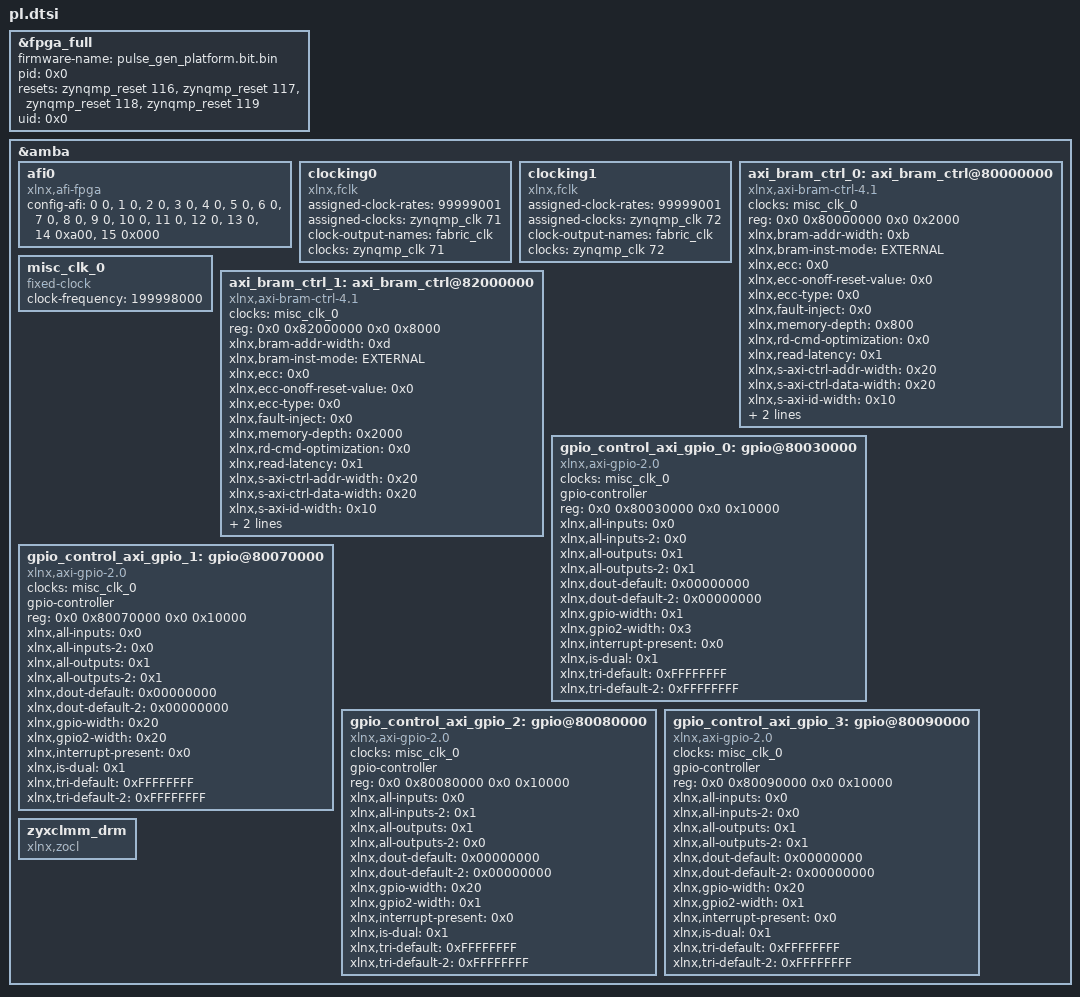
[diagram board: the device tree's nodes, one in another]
/*
 * CAUTION: This file is automatically generated by Xilinx.
 * Version: XSCT 2022.2
 * Today is: Fri Jul 31 22:00:29 2026
 */


/dts-v1/;
/plugin/;
/ {
	fragment@0 {
		target = <&fpga_full>;
		overlay0: __overlay__ {
			#address-cells = <2>;
			#size-cells = <2>;
			firmware-name = "pulse_gen_platform.bit.bin";
			pid = <0x0>;
			resets = <&zynqmp_reset 116>, <&zynqmp_reset 117>, <&zynqmp_reset 118>, <&zynqmp_reset 119>;
			uid = <0x0>;
		};
	};
	fragment@1 {
		target = <&amba>;
		overlay1: __overlay__ {
			afi0: afi0 {
				compatible = "xlnx,afi-fpga";
				config-afi = < 0 0>, <1 0>, <2 0>, <3 0>, <4 0>, <5 0>, <6 0>, <7 0>, <8 0>, <9 0>, <10 0>, <11 0>, <12 0>, <13 0>, <14 0xa00>, <15 0x000>;
			};
			clocking0: clocking0 {
				#clock-cells = <0>;
				assigned-clock-rates = <99999001>;
				assigned-clocks = <&zynqmp_clk 71>;
				clock-output-names = "fabric_clk";
				clocks = <&zynqmp_clk 71>;
				compatible = "xlnx,fclk";
			};
			clocking1: clocking1 {
				#clock-cells = <0>;
				assigned-clock-rates = <99999001>;
				assigned-clocks = <&zynqmp_clk 72>;
				clock-output-names = "fabric_clk";
				clocks = <&zynqmp_clk 72>;
				compatible = "xlnx,fclk";
			};
		};
	};
	fragment@2 {
		target = <&amba>;
		overlay2: __overlay__ {
			#address-cells = <2>;
			#size-cells = <2>;
			axi_bram_ctrl_0: axi_bram_ctrl@80000000 {
				/* This is a place holder node for a custom IP, user may need to update the entries */
				clock-names = "s_axi_aclk";
				clocks = <&misc_clk_0>;
				compatible = "xlnx,axi-bram-ctrl-4.1";
				reg = <0x0 0x80000000 0x0 0x2000>;
				xlnx,bram-addr-width = <0xb>;
				xlnx,bram-inst-mode = "EXTERNAL";
				xlnx,ecc = <0x0>;
				xlnx,ecc-onoff-reset-value = <0x0>;
				xlnx,ecc-type = <0x0>;
				xlnx,fault-inject = <0x0>;
				xlnx,memory-depth = <0x800>;
				xlnx,rd-cmd-optimization = <0x0>;
				xlnx,read-latency = <0x1>;
				xlnx,s-axi-ctrl-addr-width = <0x20>;
				xlnx,s-axi-ctrl-data-width = <0x20>;
				xlnx,s-axi-id-width = <0x10>;
				xlnx,s-axi-supports-narrow-burst = <0x1>;
				xlnx,single-port-bram = <0x1>;
			};
			misc_clk_0: misc_clk_0 {
				#clock-cells = <0>;
				clock-frequency = <199998000>;
				compatible = "fixed-clock";
			};
			axi_bram_ctrl_1: axi_bram_ctrl@82000000 {
				/* This is a place holder node for a custom IP, user may need to update the entries */
				clock-names = "s_axi_aclk";
				clocks = <&misc_clk_0>;
				compatible = "xlnx,axi-bram-ctrl-4.1";
				reg = <0x0 0x82000000 0x0 0x8000>;
				xlnx,bram-addr-width = <0xd>;
				xlnx,bram-inst-mode = "EXTERNAL";
				xlnx,ecc = <0x0>;
				xlnx,ecc-onoff-reset-value = <0x0>;
				xlnx,ecc-type = <0x0>;
				xlnx,fault-inject = <0x0>;
				xlnx,memory-depth = <0x2000>;
				xlnx,rd-cmd-optimization = <0x0>;
				xlnx,read-latency = <0x1>;
				xlnx,s-axi-ctrl-addr-width = <0x20>;
				xlnx,s-axi-ctrl-data-width = <0x20>;
				xlnx,s-axi-id-width = <0x10>;
				xlnx,s-axi-supports-narrow-burst = <0x1>;
				xlnx,single-port-bram = <0x1>;
			};
			gpio_control_axi_gpio_0: gpio@80030000 {
				#gpio-cells = <2>;
				clock-names = "s_axi_aclk";
				clocks = <&misc_clk_0>;
				compatible = "xlnx,axi-gpio-2.0", "xlnx,xps-gpio-1.00.a";
				gpio-controller ;
				reg = <0x0 0x80030000 0x0 0x10000>;
				xlnx,all-inputs = <0x0>;
				xlnx,all-inputs-2 = <0x0>;
				xlnx,all-outputs = <0x1>;
				xlnx,all-outputs-2 = <0x1>;
				xlnx,dout-default = <0x00000000>;
				xlnx,dout-default-2 = <0x00000000>;
				xlnx,gpio-width = <0x1>;
				xlnx,gpio2-width = <0x3>;
				xlnx,interrupt-present = <0x0>;
				xlnx,is-dual = <0x1>;
				xlnx,tri-default = <0xFFFFFFFF>;
				xlnx,tri-default-2 = <0xFFFFFFFF>;
			};
			gpio_control_axi_gpio_1: gpio@80070000 {
				#gpio-cells = <2>;
				clock-names = "s_axi_aclk";
				clocks = <&misc_clk_0>;
				compatible = "xlnx,axi-gpio-2.0", "xlnx,xps-gpio-1.00.a";
				gpio-controller ;
				reg = <0x0 0x80070000 0x0 0x10000>;
				xlnx,all-inputs = <0x0>;
				xlnx,all-inputs-2 = <0x0>;
				xlnx,all-outputs = <0x1>;
				xlnx,all-outputs-2 = <0x1>;
				xlnx,dout-default = <0x00000000>;
				xlnx,dout-default-2 = <0x00000000>;
				xlnx,gpio-width = <0x20>;
				xlnx,gpio2-width = <0x20>;
				xlnx,interrupt-present = <0x0>;
				xlnx,is-dual = <0x1>;
				xlnx,tri-default = <0xFFFFFFFF>;
				xlnx,tri-default-2 = <0xFFFFFFFF>;
			};
			gpio_control_axi_gpio_2: gpio@80080000 {
				#gpio-cells = <2>;
				clock-names = "s_axi_aclk";
				clocks = <&misc_clk_0>;
				compatible = "xlnx,axi-gpio-2.0", "xlnx,xps-gpio-1.00.a";
				gpio-controller ;
				reg = <0x0 0x80080000 0x0 0x10000>;
				xlnx,all-inputs = <0x0>;
				xlnx,all-inputs-2 = <0x1>;
				xlnx,all-outputs = <0x1>;
				xlnx,all-outputs-2 = <0x0>;
				xlnx,dout-default = <0x00000000>;
				xlnx,dout-default-2 = <0x00000000>;
				xlnx,gpio-width = <0x20>;
				xlnx,gpio2-width = <0x1>;
				xlnx,interrupt-present = <0x0>;
				xlnx,is-dual = <0x1>;
				xlnx,tri-default = <0xFFFFFFFF>;
				xlnx,tri-default-2 = <0xFFFFFFFF>;
			};
			gpio_control_axi_gpio_3: gpio@80090000 {
				#gpio-cells = <2>;
				clock-names = "s_axi_aclk";
				clocks = <&misc_clk_0>;
				compatible = "xlnx,axi-gpio-2.0", "xlnx,xps-gpio-1.00.a";
				gpio-controller ;
				reg = <0x0 0x80090000 0x0 0x10000>;
				xlnx,all-inputs = <0x0>;
				xlnx,all-inputs-2 = <0x0>;
				xlnx,all-outputs = <0x1>;
				xlnx,all-outputs-2 = <0x1>;
				xlnx,dout-default = <0x00000000>;
				xlnx,dout-default-2 = <0x00000000>;
				xlnx,gpio-width = <0x20>;
				xlnx,gpio2-width = <0x1>;
				xlnx,interrupt-present = <0x0>;
				xlnx,is-dual = <0x1>;
				xlnx,tri-default = <0xFFFFFFFF>;
				xlnx,tri-default-2 = <0xFFFFFFFF>;
			};
			zyxclmm_drm {
				compatible = "xlnx,zocl";
			};
		};
	};
};
